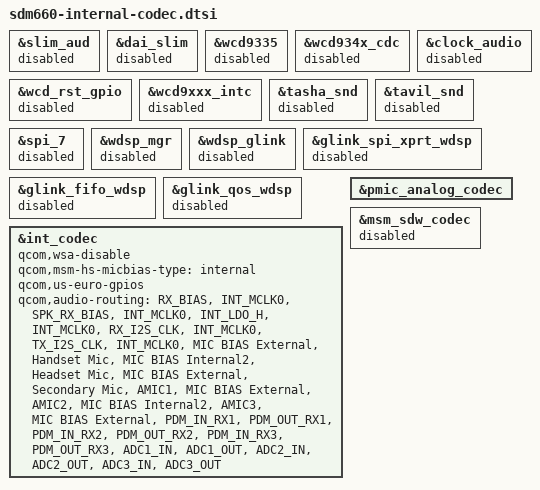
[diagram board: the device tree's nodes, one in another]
/* Copyright (c) 2017, The Linux Foundation. All rights reserved.
 *
 * This program is free software; you can redistribute it and/or modify
 * it under the terms of the GNU General Public License version 2 and
 * only version 2 as published by the Free Software Foundation.
 *
 * This program is distributed in the hope that it will be useful,
 * but WITHOUT ANY WARRANTY; without even the implied warranty of
 * MERCHANTABILITY or FITNESS FOR A PARTICULAR PURPOSE.  See the
 * GNU General Public License for more details.
 */

&slim_aud {
	status = "disabled";
};

&dai_slim {
	status = "disabled";
};

&wcd9335 {
	status = "disabled";
};

&wcd934x_cdc {
	status = "disabled";
};

&clock_audio {
	status = "disabled";
};

&wcd_rst_gpio {
	status = "disabled";
};

&wcd9xxx_intc {
	status = "disabled";
};

&tasha_snd {
	status = "disabled";
};

&tavil_snd {
	status = "disabled";
};

&spi_7 {
	status = "disabled";
};

&wdsp_mgr {
	status = "disabled";
};

&wdsp_glink {
	status = "disabled";
};

&glink_spi_xprt_wdsp {
	status = "disabled";
};

&glink_fifo_wdsp {
	status = "disabled";
};

&glink_qos_wdsp {
	status = "disabled";
};

&int_codec {
	status = "okay";
	/*Chk30757,liujun5.wt modify 20200413 ,modify for smart PA bringup*/
       qcom,wsa-disable;
	qcom,msm-hs-micbias-type = "internal";
	qcom,us-euro-gpios;
	qcom,audio-routing =
	"RX_BIAS", "INT_MCLK0",
	"SPK_RX_BIAS", "INT_MCLK0",
	"INT_LDO_H", "INT_MCLK0",
	"RX_I2S_CLK", "INT_MCLK0",
	"TX_I2S_CLK", "INT_MCLK0",
	"MIC BIAS External", "Handset Mic",
	"MIC BIAS Internal2", "Headset Mic",
	"MIC BIAS External", "Secondary Mic",
	"AMIC1", "MIC BIAS External",
	"AMIC2", "MIC BIAS Internal2",
	"AMIC3", "MIC BIAS External",
	"PDM_IN_RX1", "PDM_OUT_RX1",
	"PDM_IN_RX2", "PDM_OUT_RX2",
	"PDM_IN_RX3", "PDM_OUT_RX3",
	"ADC1_IN", "ADC1_OUT",
	"ADC2_IN", "ADC2_OUT",
	"ADC3_IN", "ADC3_OUT";
};
/*-Chk30757,liujun5.wt modify 20200413 ,modify for smart PA bringup*/

&pmic_analog_codec {
	status = "okay";
};

&msm_sdw_codec {
	/*Chk30757,liujun5.wt modify 20200413 ,modify for smart PA bringup*/
	status = "disabled";
};
